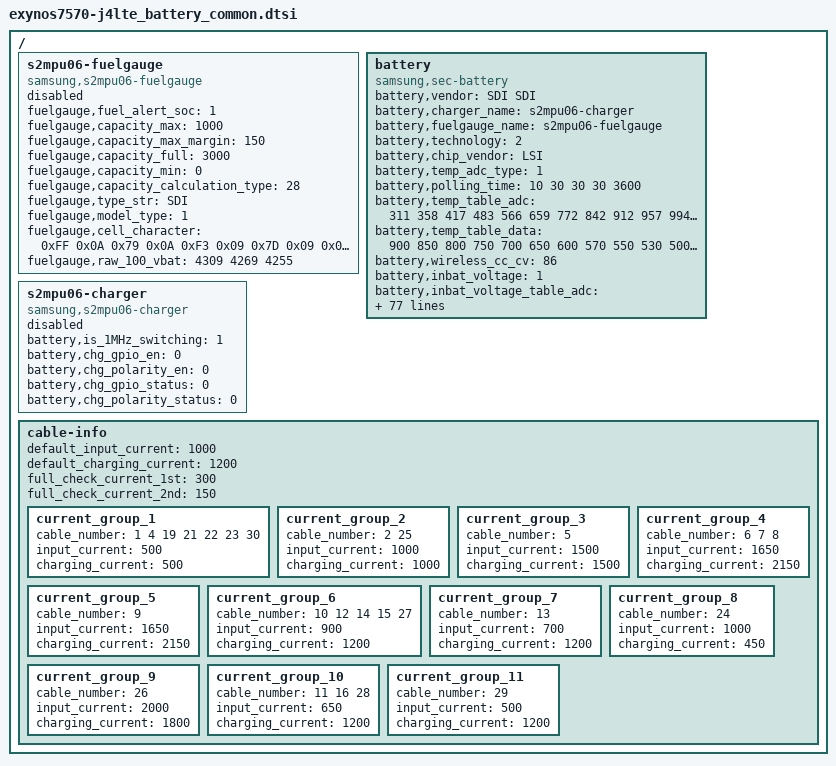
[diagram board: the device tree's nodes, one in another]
/*
 * SAMSUNG UNIVERSAL7570 board device tree source
 *
 * Copyright (c) 2018 Samsung Electronics Co., Ltd.
 *		http://www.samsung.com
 *
 * This program is free software; you can redistribute it and/or modify
 * it under the terms of the GNU General Public License version 2 as
 * published by the Free Software Foundation.
*/

/ {
	s2mpu06-fuelgauge {
		status = "disable";
		compatible = "samsung,s2mpu06-fuelgauge";
		fuelgauge,fuel_alert_soc = <1>;
		fuelgauge,capacity_max = <1000>;
		fuelgauge,capacity_max_margin = <150>;
		fuelgauge,capacity_full = <3000>;
		fuelgauge,capacity_min = <0>;
		fuelgauge,capacity_calculation_type = <28>;
		fuelgauge,type_str = "SDI";
		fuelgauge,model_type = <1>;

		fuelgauge,cell_character = < 
				/* 4.35V Cell character*/
				/* Cell character 0 0x34 ~ 0xD7 */
				0xFF 0x0A 0x79 0x0A 0xF3 0x09 0x7D 0x09 0x0D 0x09
				0xA6 0x08 0x35 0x08 0xD0 0x07 0x8F 0x07 0x38 0x07
				0xD7 0x06 0x9C 0x06 0x73 0x06 0x55 0x06 0x3B 0x06
				0x32 0x06 0x17 0x06 0xDF 0x05 0x8D 0x05 0x88 0x05
				0xEB 0x02 0x02 0x02 0x6A 0x08 0x00 0x08 0x95 0x07
				0x2B 0x07 0xC0 0x06 0x56 0x06 0xEB 0x05 0x81 0x05
				0x16 0x05 0xAC 0x04 0x41 0x04 0xD7 0x03 0x6C 0x03
				0x02 0x03 0x97 0x02 0x2D 0x02 0xC2 0x01 0x58 0x01
				0xED 0x00 0x83 0x00 0x18 0x00 0xF8 0x0F 0xFE 0x29
				0xDC 0x29 0x8A 0x29 0x4D 0x29 0x28 0x1F 0x23 0x10
				0x21 0x21 0x14 0x21 0xF2 0xF7 0xE6 0xF7 0xD3 0xDE
				0xCA 0xD4 0xD3 0xD4 0x40 0x80 0x26 0x33 0x26 0x40
				0x26 0x5C 0x26 0x5C 0x26 0x5C 0xFF 0xFF 0x02 0x05
				0x14 0x0B 0x03 0x12 0x06 0x1C 0x0C 0x1C 0x10 0x1C
				0x1F 0x1F 0x3C 0x3C 0x3C 0x3C 0x3C 0x3C 0x3B 0x3C
				0x3C 0x3C 0x3D 0x3D 0x3F 0x41 0x42 0x46 0x4C 0x58
				0x80 0xCD 0xFF 0xFF
				/* Cell character 1, 0x0F ~ 0x13 */
				0xCD 0xB8 0x0B 0x00 0x00
 
				/* 4.33V Cell character*/
				/* Cell character 0, 0x34 ~ 0xD7 */
				0xA9 0x0A 0xA9 0x0A 0x28 0x0A 0xA7 0x09 0x36 0x09
				0xCA 0x08 0x77 0x08 0xE9 0x07 0xB1 0x07 0x67 0x07
				0x00 0x07 0xB4 0x06 0x85 0x06 0x62 0x06 0x45 0x06
				0x37 0x06 0x2B 0x06 0x03 0x06 0xBF 0x05 0x85 0x05
				0x74 0x05 0xF0 0x03 0x6F 0x08 0x6F 0x08 0x00 0x08
				0x91 0x07 0x22 0x07 0xB3 0x06 0x44 0x06 0xD5 0x05
				0x66 0x05 0xF7 0x04 0x88 0x04 0x19 0x04 0xAA 0x03
				0x3B 0x03 0xCC 0x02 0x5D 0x02 0xEE 0x01 0x7F 0x01
				0x10 0x01 0xA2 0x00 0x33 0x00 0xDA 0x0F 0xFE 0x29
				0xDC 0x29 0x8A 0x29 0x4D 0x29 0x28 0x1F 0x23 0x10
				0x21 0x21 0x14 0x21 0xF7 0xF7 0xE6 0xF7 0xD3 0xDE
				0xCA 0xD4 0xD3 0xD4 0x40 0x80 0x26 0x33 0x26 0x40
				0x26 0x5C 0x26 0x5C 0x26 0x5C 0xFF 0xFF 0x02 0x05
				0x14 0x0B 0x03 0x12 0x06 0x1C 0x0C 0x1C 0x10 0x1C
				0x1F 0x1F 0x40 0x40 0x40 0x3F 0x3E 0x3F 0x3F 0x40
				0x40 0x3F 0x40 0x41 0x43 0x46 0x48 0x4B 0x54 0x60
				0x71 0x8B 0xB9 0xCD
				/* Cell character 1, 0x0F ~ 0x13 */
				0xCD 0xA0 0x0A 0x00 0x00
 
				/* 4.31V Cell character*/
				/* Cell character 0, 0x34 ~ 0xD7 */
				0xA9 0x0A 0xA9 0x0A 0x28 0x0A 0xA7 0x09 0x36 0x09
				0xCA 0x08 0x77 0x08 0xE9 0x07 0xB1 0x07 0x67 0x07
				0x00 0x07 0xB4 0x06 0x85 0x06 0x62 0x06 0x45 0x06
				0x37 0x06 0x2B 0x06 0x03 0x06 0xBF 0x05 0x85 0x05
				0x74 0x05 0xF0 0x03 0x89 0x08 0x89 0x08 0x19 0x08
				0xA9 0x07 0x38 0x07 0xC8 0x06 0x58 0x06 0xE7 0x05
				0x77 0x05 0x07 0x05 0x96 0x04 0x26 0x04 0xB6 0x03
				0x45 0x03 0xD5 0x02 0x65 0x02 0xF4 0x01 0x84 0x01
				0x14 0x01 0xA3 0x00 0x33 0x00 0xD9 0x0F 0xFE 0x29
				0xDC 0x29 0x8A 0x29 0x4D 0x29 0x28 0x1F 0x23 0x10
				0x21 0x21 0x14 0x21 0xF7 0xF7 0xE6 0xF7 0xD3 0xDE
				0xCA 0xD4 0xD3 0xD4 0x40 0x80 0x26 0x33 0x26 0x40
				0x26 0x5C 0x26 0x5C 0x26 0x5C 0xFF 0xFF 0x02 0x05
				0x14 0x0B 0x03 0x12 0x06 0x1C 0x0C 0x1C 0x10 0x1C
				0x1F 0x1F 0x40 0x40 0x40 0x3F 0x3E 0x3F 0x3F 0x40
				0x40 0x3F 0x40 0x41 0x43 0x46 0x48 0x4B 0x54 0x60
				0x71 0x8B 0xB9 0x05
				
				/* Cell character 1, 0x0F ~ 0x13 */ 
				0xCD 0x7F 0x0A 0x00 0x00
				>;
				
				fuelgauge,raw_100_vbat = <4309 4269 4255>;
	};

	battery {
		status = "okay";

		pinctrl-names = "default";

		compatible = "samsung,sec-battery";
		battery,vendor = "SDI SDI";
		battery,charger_name = "s2mpu06-charger";
		battery,fuelgauge_name = "s2mpu06-fuelgauge";
		battery,technology = <2>; /* POWER_SUPPLY_TECHNOLOGY_LION */

		battery,chip_vendor = "LSI";

		battery,temp_adc_type = <1>; /* SEC_BATTERY_ADC_TYPE_AP */

		battery,polling_time = <10 30 30 30 3600>;

		battery,temp_table_adc = <311 358 417 483 566 659 772 842 912 957
                                  994 1085 1150 1228 1361 1377 1456 1548 1581 1782 
                                  2026 2252 2477 2578 2712 2796 2937 3010 3126 3227
                                  3302 3446 3574 3681>;

		battery,temp_table_data = <900 850 800 750 700 650 600 570 550 530
                             	   500 470 450 430 410 400 380 360 350 300 
								   250 200 150 130 100 80 50 30 0 (-30) 
								   (-50) (-100) (-150) (-200)>;

		battery,wireless_cc_cv = <86>;
		battery,inbat_voltage = <1>;

		battery,inbat_voltage_table_adc = <
						2789 2781 2764 2747 2737 2706 2698 2678 2656 2627
						2608 2601 2584 2565 2556 2545 2540 2528 2514 2505
						2491 2483 2472 2453 2437 2419 2398 2374 2365 2348
						2319 2286
						>;

		battery,inbat_voltage_table_data = <
						4350 4330 4300 4270 4250 4200 4180 4140 4100 4050
						4010 4000 3980 3950 3930 3910 3900 3880 3860 3840
						3810 3800 3780 3750 3720 3680 3640 3600 3580 3550
						3500 3450
						>;

		battery,adc_check_count = <5>;

		battery,cable_check_type = <4>; /* SEC_BATTERY_CABLE_CHECK_PSY */
		battery,cable_source_type = <1>; /* SEC_BATTERY_CABLE_SOURCE_EXTERNAL */
		battery,polling_type = <1>; /* SEC_BATTERY_MONITOR_ALARM */
		battery,monitor_initial_count = <0>;

		battery,battery_check_type = <5>; /* SEC_BATTERY_CHECK_CHARGER */
		battery,check_count = <0>;

		battery,ovp_uvlo_check_type = <3>; /* SEC_BATTERY_OVP_UVLO_CHGPOLLING */

		battery,check_adc_max = <1440>;
		battery,check_adc_min = <0>;

		battery,thermal_source = <2>; /* SEC_BATTERY_THERMAL_SOURCE_ADC */

		battery,temp_check_type = <2>; /* SEC_BATTERY_TEMP_CHECK_TEMP */
		battery,temp_check_count = <1>;
		battery,temp_highlimit_threshold_normal = <800>;
		battery,temp_highlimit_recovery_normal = <750>;
		battery,temp_high_threshold_normal = <500>;
		battery,temp_high_recovery_normal = <450>;
		battery,temp_low_threshold_normal = <0>;
		battery,temp_low_recovery_normal = <50>;
		battery,temp_highlimit_threshold_lpm = <800>;
		battery,temp_highlimit_recovery_lpm = <750>;
		battery,temp_high_threshold_lpm = <500>;
		battery,temp_high_recovery_lpm = <450>;
		battery,temp_low_threshold_lpm = <0>;
		battery,temp_low_recovery_lpm = <50>;

		battery,full_check_type = <7>; /* SEC_BATTERY_FULLCHARGED_CHGPSY */
		battery,full_check_type_2nd = <7>; /* SEC_BATTERY_FULLCHARGED_CHGPSY */
		battery,full_check_count = <1>;
		battery,chg_gpio_full_check = <0>;
		battery,chg_polarity_full_check = <1>;

		battery,chg_high_temp_1st = <530>;
		battery,chg_high_temp_2nd = <530>;
		battery,chg_high_temp_recovery = <525>;
		battery,chg_charging_limit_current = <1300>;
		battery,chg_charging_limit_current_2nd = <1300>;
		battery,chg_skip_check_capacity = <10>;
		battery,chg_skip_check_time = <600>;

		battery,wpc_high_temp = <420>;
		battery,wpc_high_temp_recovery = <410>;
		battery,wpc_charging_limit_current = <450>;

		/* SEC_BATTERY_FULL_CONDITION_SOC |
		   SEC_BATTERY_FULL_CONDITION_NOTIMEFULL |
		   SEC_BATTERY_FULL_CONDITION_VCELL */
		battery,full_condition_type = <15>;
		battery,full_condition_soc = <93>;
		battery,full_condition_vcell = <4250>;

		battery,recharge_check_count = <2>;
		battery,recharge_condition_type = <4>; /* SEC_BATTERY_RECHARGE_CONDITION_VCELL */
		battery,recharge_condition_soc = <98>;
		battery,recharge_condition_vcell = <4250>;

		battery,standard_curr = <1034>;
		battery,recharging_expired_time = <5400>;
		battery,expired_time = <17400>; /* 2nd EOC Time + Margin i.e 210 + 80 */

		battery,chg_float_voltage = <4350>;

		battery,swelling_high_temp_block = <410>;
		battery,swelling_high_temp_recov = <390>;

		battery,swelling_low_temp_2step_mode = <1>;
		battery,swelling_low_temp_block_1st = <150>;
		battery,swelling_low_temp_recov_1st = <200>;
		battery,swelling_low_temp_block_2nd = <50>;
		battery,swelling_low_temp_recov_2nd = <100>;

		battery,swelling_low_temp_current = <740>;	/* 0.3C */
		battery,swelling_low_temp_topoff = <150>;	/* 0.05C */
		battery,swelling_high_temp_current = <1120>;	/* 0.45C */
		battery,swelling_high_temp_topoff = <150>;	/* 0.05C */

		battery,swelling_drop_float_voltage = <4150>;
		battery,swelling_high_rechg_voltage = <4000>;
		battery,swelling_low_rechg_voltage = <4000>;

                battery,charging_by_single;
                battery,call_event_siop_level = <100>;

                battery,call_event_input = <1200>;
                battery,call_event_output = <720>;

		battery,battery_full_capacity = <3000>;

		io-channels = <&exynos_adc 1>, <&exynos_adc 5>;
		io-channel-names = "adc-temp", "adc-in-bat";
		#io-channel-cells = <2>;
		io-channel-ranges;
		
		/* cycle, chg_float_voltage, recharge_condition_vcell, full_condition_vcell, full_condition_soc */
		battery,age_data = <0 4350 4250 4250 93	/*4.35*/
							28 4330 4230 4230 91	/*4.33*/
							36 4310 4210 4210 89	/*4.31*/
							>;
	};

	s2mpu06-charger {
		status = "disable";
		compatible = "samsung,s2mpu06-charger";
		battery,is_1MHz_switching = <1>;
		battery,chg_gpio_en = <0>;
		battery,chg_polarity_en = <0>;
		battery,chg_gpio_status = <0>;
		battery,chg_polarity_status = <0>;
	};

/* sec_battery_cable
 *   0	UNKNOWN,
 *   1	NONE,
 *   2	PREPARE_TA,
 *   3	TA,
 *   4	USB,
 *   5	USB_CDP,
 *   6	9V_TA,
 *   7	9V_ERR,
 *   8	9V_UNKNOWN,
 *   9	12V_TA,
 *  10	WIRELESS,
 *  11	HV_WIRELESS,
 *  12	PMA_WIRELESS,
 *  13	WIRELESS_PACK,
 *  14	WIRELESS_PACK_TA,
 *  15	WIRELESS_STAND,
 *  16	WIRELESS_HV_STAND,
 *  17	QC20,
 *  18	QC30,
 *  19	PDIC,
 *  20	UARTOFF,
 *  21	OTG,
 *  22	LAN_HUB,
 *  23	POWER_SHARING,
 *  24	HMT_CONNECTED,
 *  25	HMT_CHARGE,
 *  26	HV_TA_CHG_LIMIT,
 *  27	WIRELESS_VEHICLE,
 *  28	WIRELESS_HV_VEHICLE,
 *  29	PREPARE_WIRELESS_HV,
 *  30	TIMEOUT,
 *  31	CABLE_MAX,
 */
	cable-info {
		default_input_current = <1000>;
		default_charging_current = <1200>;
		full_check_current_1st = <300>;
		full_check_current_2nd = <150>;

		current_group_1 {
			cable_number = <1 4 19 21 22 23 30>;
			input_current = <500>;
			charging_current = <500>;
		};

		current_group_2 {
			cable_number = <2 25>;
			input_current = <1000>;
			charging_current = <1000>;
		};

		current_group_3 {
			cable_number = <5>;
			input_current = <1500>;
			charging_current = <1500>;
		};

		current_group_4 {
			cable_number = <6 7 8>;
			input_current = <1650>;
			charging_current = <2150>;
		};

		current_group_5 {
			cable_number = <9>;
			input_current = <1650>;
			charging_current = <2150>;
		};

		current_group_6 {
			cable_number = <10 12 14 15 27>;
			input_current = <900>;
			charging_current = <1200>;
		};

		current_group_7 {
			cable_number = <13>;
			input_current = <700>;
			charging_current = <1200>;
		};

		current_group_8 {
			cable_number = <24>;
			input_current = <1000>;
			charging_current = <450>;
		};

		current_group_9 {
			cable_number = <26>;
			input_current = <2000>;
			charging_current = <1800>;
		};

		current_group_10 {
			cable_number = <11 16 28>;
			input_current = <650>;
			charging_current = <1200>;
		};

		current_group_11 {
			cable_number = <29>;
			input_current = <500>;
			charging_current = <1200>;
		};
	};
};

